VERSION ""

NS_ :

BS_:

BU_:

BO_ 773 pylon_battery_heartbeat: 8 Vector__XXX

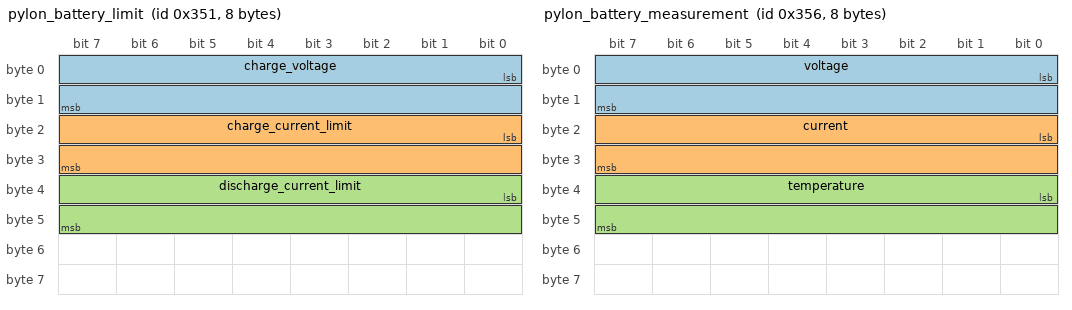
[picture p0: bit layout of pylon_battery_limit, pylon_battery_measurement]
BO_ 849 pylon_battery_limit: 8 Vector__XXX
	SG_ charge_voltage : 0|16@1+ (0.1,0) [0|0] "V" Vector__XXX
	SG_ charge_current_limit : 16|16@1- (0.1,0) [0|0] "A" Vector__XXX
	SG_ discharge_current_limit : 32|16@1- (0.1,0) [0|0] "A" Vector__XXX

BO_ 853 pylon_battery_state_of: 8 Vector__XXX
	SG_ charge : 0|16@1+ (1,0) [0|0] "%" Vector__XXX
	SG_ health : 16|16@1+ (1,0) [0|0] "%" Vector__XXX

BO_ 854 pylon_battery_measurement: 8 Vector__XXX
	SG_ voltage : 0|16@1- (0.01,0) [0|0] "V" Vector__XXX
	SG_ current : 16|16@1- (0.1,0) [0|0] "A" Vector__XXX
	SG_ temperature : 32|16@1- (0.1,0) [0|0] "C" Vector__XXX

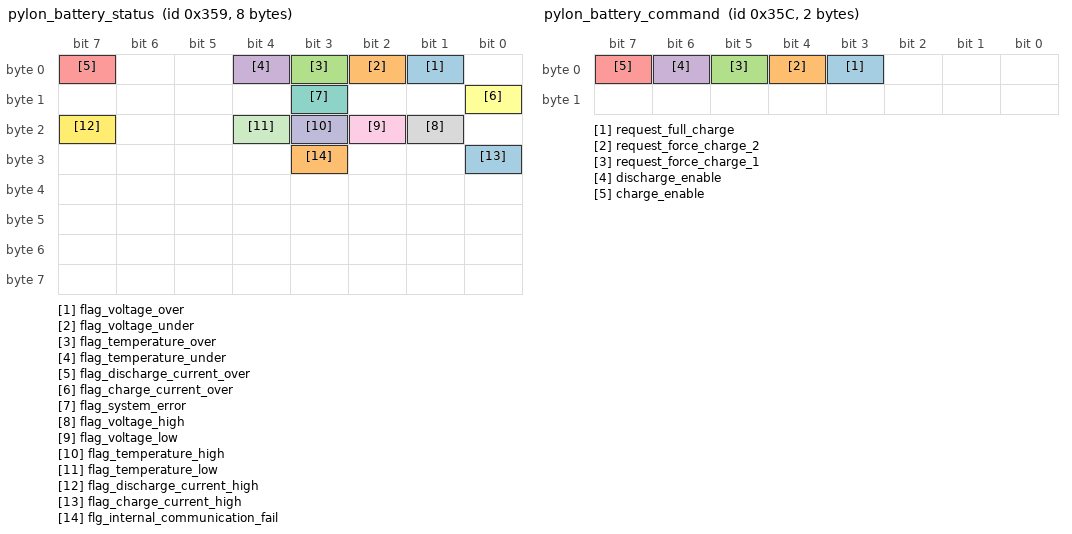
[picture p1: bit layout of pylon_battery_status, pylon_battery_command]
BO_ 857 pylon_battery_status: 8 Vector__XXX
	SG_ flag_voltage_over : 1|1@1+ (1,0) [0|1] "Boolean" Vector__XXX
	SG_ flag_voltage_under : 2|1@1+ (1,0) [0|1] "Boolean" Vector__XXX
	SG_ flag_temperature_over : 3|1@1+ (1,0) [0|1] "Boolean" Vector__XXX
	SG_ flag_temperature_under : 4|1@1+ (1,0) [0|1] "Boolean" Vector__XXX
	SG_ flag_discharge_current_over : 7|1@1+ (1,0) [0|1] "Boolean" Vector__XXX
	SG_ flag_charge_current_over : 8|1@1+ (1,0) [0|1] "Boolean" Vector__XXX
	SG_ flag_system_error : 11|1@1+ (1,0) [0|1] "Boolean" Vector__XXX
	SG_ flag_voltage_high : 17|1@1+ (1,0) [0|1] "Boolean" Vector__XXX
	SG_ flag_voltage_low : 18|1@1+ (1,0) [0|1] "Boolean" Vector__XXX
	SG_ flag_temperature_high : 19|1@1+ (1,0) [0|1] "Boolean" Vector__XXX
	SG_ flag_temperature_low : 20|1@1+ (1,0) [0|1] "Boolean" Vector__XXX
	SG_ flag_discharge_current_high : 23|1@1+ (1,0) [0|1] "Boolean" Vector__XXX
	SG_ flag_charge_current_high : 24|1@1+ (1,0) [0|1] "Boolean" Vector__XXX
	SG_ flg_internal_communication_fail : 27|1@1+ (1,0) [0|1] "Boolean" Vector__XXX

BO_ 860 pylon_battery_command: 2 Vector__XXX
	SG_ request_full_charge : 3|1@1+ (1,0) [0|1] "Boolean" Vector__XXX
	SG_ request_force_charge_2 : 4|1@1+ (1,0) [0|1] "Boolean" Vector__XXX
	SG_ request_force_charge_1 : 5|1@1+ (1,0) [0|1] "Boolean" Vector__XXX
	SG_ discharge_enable : 6|1@1+ (1,0) [0|1] "Boolean" Vector__XXX
	SG_ charge_enable : 7|1@1+ (1,0) [0|1] "Boolean" Vector__XXX

BO_ 862 pylon_battery_identification: 0 Vector__XXX
	SG_ mfg_name : 0|16@1+ (1,0) [0|0] "ASCII" Vector__XXX
